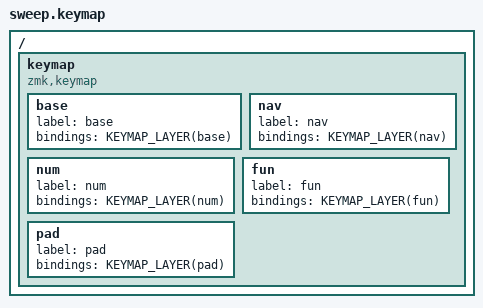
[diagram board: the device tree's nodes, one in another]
/*
 * sweep (Ferris Sweep) — thin keymap. Uses the cradio_left/cradio_right shields
 * built into ZMK core (nice_nano). Pure 3x5 + 2-thumbs/side core with a contiguous
 * 0..33 matrix, so it reuses the shared generic adapter geom_3x5_2.h. All content
 * lives in config/shared/.
 */

#include <behaviors.dtsi>
#include <dt-bindings/zmk/keys.h>
#include <dt-bindings/zmk/bt.h>
#include <dt-bindings/zmk/outputs.h>

#include "geometry/geom_3x5_2.h"

#include "shared/keys_de.h"
#include "shared/settings.dtsi"
#include "shared/behaviors.dtsi"
#include "shared/macros.dtsi"
#include "shared/combos.dtsi"
#include "shared/core_blocks.dtsi"

/ {
    keymap {
        compatible = "zmk,keymap";

        base { label = "base"; bindings = <KEYMAP_LAYER(base)>; };
        nav  { label = "nav";  bindings = <KEYMAP_LAYER(nav)>;  };
        num  { label = "num";  bindings = <KEYMAP_LAYER(num)>;  };
        fun  { label = "fun";  bindings = <KEYMAP_LAYER(fun)>;  };
        pad  { label = "pad";  bindings = <KEYMAP_LAYER(pad)>;  };
    };
};
